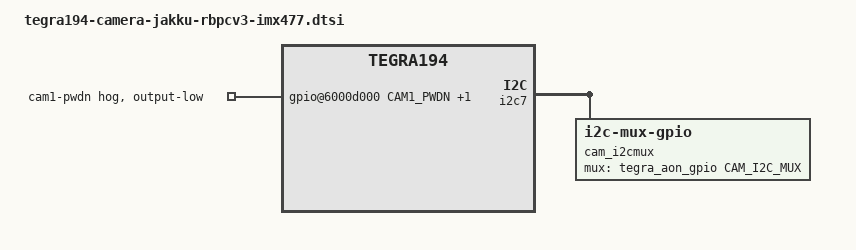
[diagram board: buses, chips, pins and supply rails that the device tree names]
/*
 * Copyright (c) 2021, NVIDIA CORPORATION.  All rights reserved.
 *
 * This program is free software; you can redistribute it and/or modify
 * it under the terms of the GNU General Public License as published by
 * the Free Software Foundation; either version 2 of the License, or
 * (at your option) any later version.
 *
 * This program is distributed in the hope that it will be useful, but WITHOUT
 * ANY WARRANTY; without even the implied warranty of MERCHANTABILITY or
 * FITNESS FOR A PARTICULAR PURPOSE.  See the GNU General Public License for
 * more details.
 *
 * You should have received a copy of the GNU General Public License
 * along with this program.  If not, see <http://www.gnu.org/licenses/>.
 */

#include "tegra194-camera-rbpcv3-imx477.dtsi"

#define CAM0_PWDN	TEGRA194_MAIN_GPIO(P, 4)
#define CAM1_PWDN	TEGRA194_MAIN_GPIO(P, 5)
#define CAM_I2C_MUX 	TEGRA194_AON_GPIO(CC, 3)

/ {
	cam_i2cmux {
		compatible = "i2c-mux-gpio";
		#address-cells = <1>;
		#size-cells = <0>;
		mux-gpios = <&tegra_aon_gpio CAM_I2C_MUX GPIO_ACTIVE_HIGH>;
		i2c-parent = <&i2c7>;
		i2c@0 {
			reg = <0>;
			#address-cells = <1>;
			#size-cells = <0>;
			rbpcv3_imx477_a@1a {
				status = "disabled";
				reset-gpios = <&tegra_main_gpio CAM0_PWDN GPIO_ACTIVE_HIGH>;
			};
		};
		i2c@1 {
			reg = <1>;
			#address-cells = <1>;
			#size-cells = <0>;
			rbpcv3_imx477_c@1a {
				status = "disabled";
				reset-gpios = <&tegra_main_gpio CAM1_PWDN GPIO_ACTIVE_HIGH>;
			};
		};
	};

	gpio@6000d000 {
		camera-control-output-low {
			gpio-hog;
			output-low;
			gpios = < CAM1_PWDN 0  CAM0_PWDN 0>;
			label = "cam1-pwdn", "cam0-pwdn";
		};
	};
};
